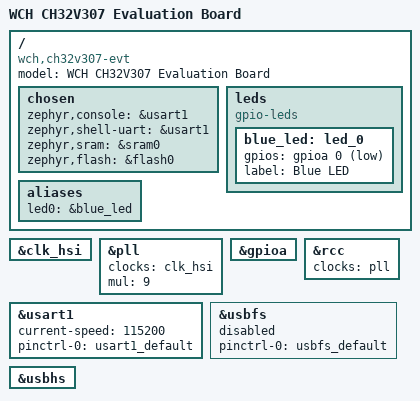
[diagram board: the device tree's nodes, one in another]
/*
 * Copyright (c) 2026 Scott King
 *
 * SPDX-License-Identifier: Apache-2.0
 */

/dts-v1/;

#include <wch/ch32v307/ch32v307vc.dtsi>
#include "ch32v307_evt-pinctrl.dtsi"

/ {
	model = "WCH CH32V307 Evaluation Board";
	compatible = "wch,ch32v307-evt", "wch,ch32v307";

	chosen {
		zephyr,console = &usart1;
		zephyr,shell-uart = &usart1;
		zephyr,sram = &sram0;
		zephyr,flash = &flash0;
	};

	leds {
		compatible = "gpio-leds";
		blue_led: led_0 {
			gpios = <&gpioa 0 GPIO_ACTIVE_LOW>;
			label = "Blue LED";
		};
	};

	aliases {
		led0 = &blue_led;
	};
};

&clk_hsi {
	status = "okay";
};

&pll {
	status = "okay";
	clocks = <&clk_hsi>;
	mul = <9>;
};

&usart1 {
	status = "okay";
	current-speed = <115200>;
	pinctrl-0 = <&usart1_default>;
	pinctrl-names = "default";
};

&gpioa {
	status = "okay";
};

&rcc {
	status = "okay";
	clocks = <&pll>;
};

&usbfs {
	status = "disabled";
	pinctrl-0 = <&usbfs_default>;
	pinctrl-names = "default";
};

zephyr_udc0: &usbhs {
	status = "okay";
};
